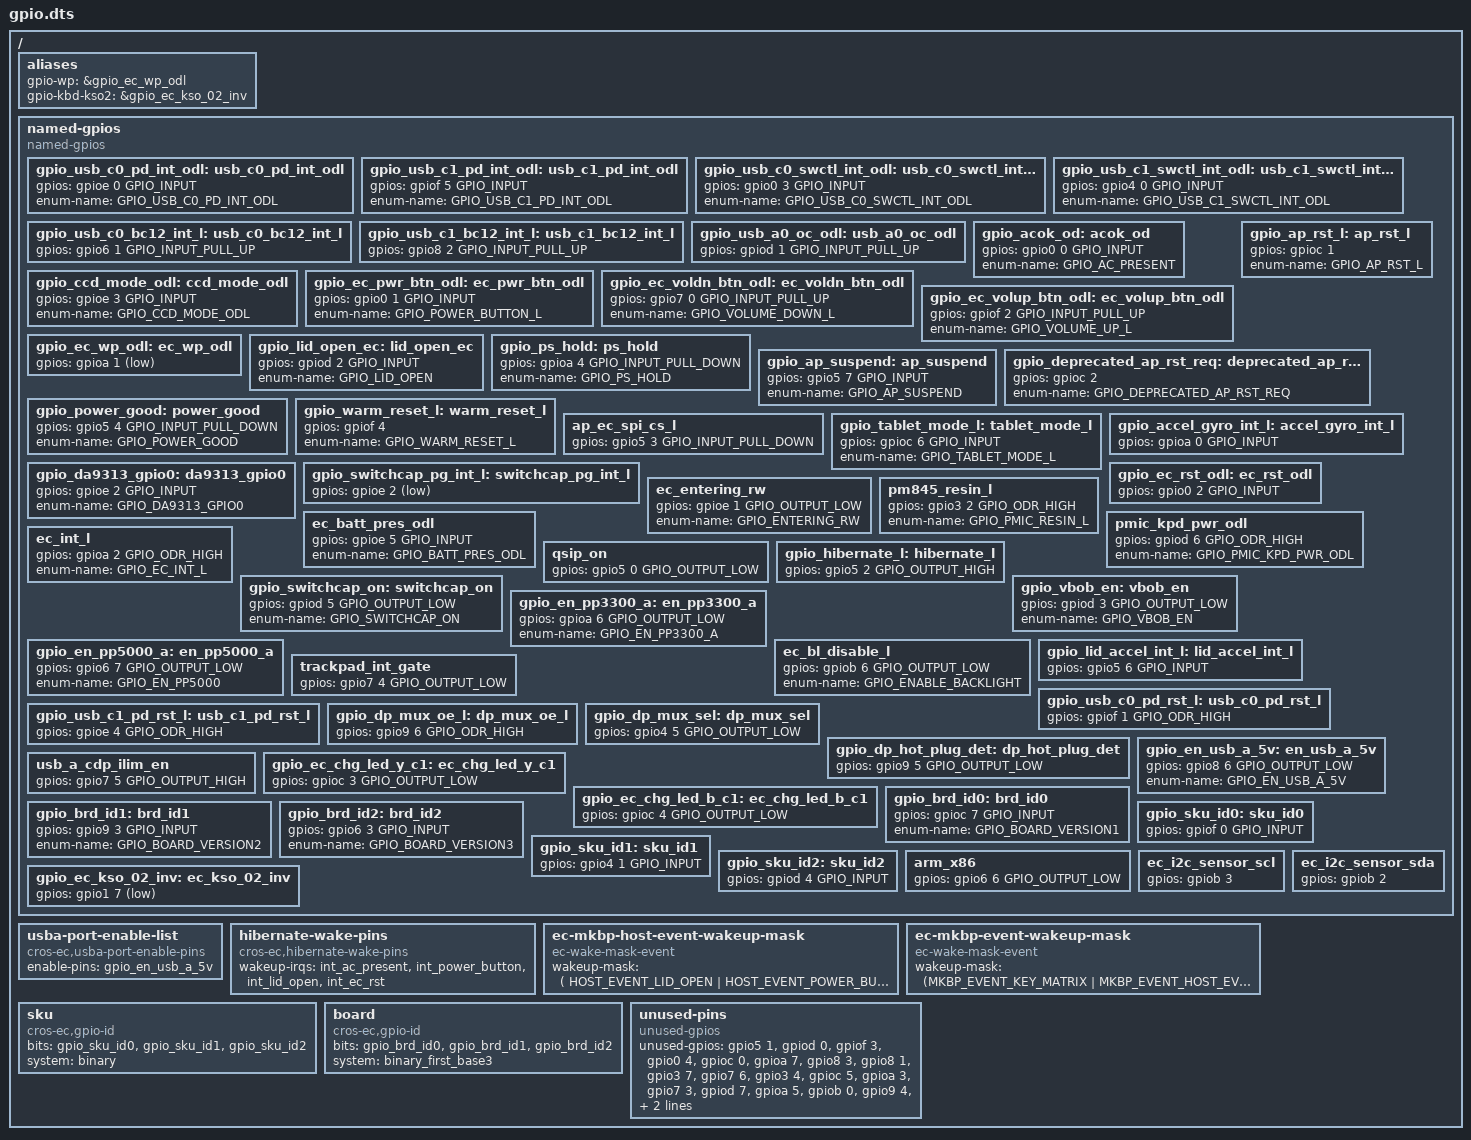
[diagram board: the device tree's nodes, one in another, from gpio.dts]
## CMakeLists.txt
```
# Copyright 2021 The ChromiumOS Authors. All rights reserved.
# Use of this source code is governed by a BSD-style license that can be
# found in the LICENSE file.

cmake_minimum_required(VERSION 3.13.1)

find_package(Zephyr REQUIRED HINTS $ENV{ZEPHYR_BASE})
project(lazor)

cros_ec_library_include_directories(include)

zephyr_library_sources_ifdef(CONFIG_PLATFORM_EC_USBC
  "src/power.c"
  "src/usb_pd_policy.c"
  "src/usbc_config.c")

zephyr_library_sources(
  "src/sku.c"
  "src/switchcap.c")

# Board specific implementation
zephyr_library_sources_ifdef(CONFIG_PLATFORM_EC_I2C
  "src/i2c.c")
```

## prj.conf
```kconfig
# Copyright 2021 The ChromiumOS Authors
# Use of this source code is governed by a BSD-style license that can be
# found in the LICENSE file.

CONFIG_CROS_EC=y
#
# Lazor actually has a NPCX7M6FC, but
# the NPCX7M7FC is actually the same die, without the
# extra RAM being tested. The code size really could
# do with the extra space, so we pretend the EC is the
# part with the larger RAM. YMMV.
#
CONFIG_SOC_NPCX7M7FC=y
CONFIG_SOC_SERIES_NPCX7=y
CONFIG_SHIMMED_TASKS=y
CONFIG_PLATFORM_EC=y
CONFIG_PLATFORM_EC_BRINGUP=y
CONFIG_PLATFORM_EC_EXTPOWER_GPIO=y
CONFIG_PLATFORM_EC_SWITCH=y
CONFIG_PLATFORM_EC_LID_SWITCH=y
CONFIG_PLATFORM_EC_BACKLIGHT_LID=y
CONFIG_PLATFORM_EC_POWER_BUTTON=y

# PWM
CONFIG_PWM=y
CONFIG_PWM_SHELL=n

# Application Processor is Qualcomm SC7180
CONFIG_AP_ARM_QUALCOMM_SC7180=y

# Board version is selected over GPIO board ID pins.
CONFIG_PLATFORM_EC_BOARD_VERSION_GPIO=y

# LN9310 Switchcap
CONFIG_PLATFORM_EC_SWITCHCAP_LN9310=y

# Power Sequencing
CONFIG_PLATFORM_EC_POWERSEQ=y
CONFIG_PLATFORM_EC_POWERSEQ_HOST_SLEEP=y
CONFIG_PLATFORM_EC_POWER_SLEEP_FAILURE_DETECTION=y
CONFIG_PLATFORM_EC_CHIPSET_RESET_HOOK=y
CONFIG_PLATFORM_EC_CHIPSET_RESUME_INIT_HOOK=y

# Trogdor family does not use EFS2
CONFIG_PLATFORM_EC_VBOOT_EFS2=n

# MKBP event
CONFIG_PLATFORM_EC_MKBP_EVENT=y
CONFIG_PLATFORM_EC_MKBP_USE_GPIO=y

# Keyboard
CONFIG_PLATFORM_EC_KEYBOARD=y
CONFIG_PLATFORM_EC_KEYBOARD_PROTOCOL_MKBP=y
CONFIG_PLATFORM_EC_MKBP_INPUT_DEVICES=y
CONFIG_PLATFORM_EC_KEYBOARD_COL2_INVERTED=y
CONFIG_PLATFORM_EC_VOLUME_BUTTONS=y
CONFIG_PLATFORM_EC_CMD_BUTTON=y
CONFIG_CROS_KB_RAW_NPCX=y

# ADC
CONFIG_ADC=y
CONFIG_ADC_SHELL=n

# Battery
CONFIG_PLATFORM_EC_BATTERY=y
CONFIG_PLATFORM_EC_BATTERY_SMART=y
CONFIG_PLATFORM_EC_I2C_VIRTUAL_BATTERY=y
CONFIG_PLATFORM_EC_I2C_PASSTHRU_RESTRICTED=y
CONFIG_PLATFORM_EC_BATTERY_FUEL_GAUGE=y
CONFIG_PLATFORM_EC_BATTERY_CUT_OFF=y
CONFIG_PLATFORM_EC_BATTERY_PRESENT_GPIO=y
CONFIG_PLATFORM_EC_CHARGER_ISL9238=y
CONFIG_PLATFORM_EC_CHARGE_RAMP_HW=y
CONFIG_PLATFORM_EC_USE_BATTERY_DEVICE_CHEMISTRY=y
CONFIG_PLATFORM_EC_BATTERY_DEVICE_CHEMISTRY="LION"
CONFIG_PLATFORM_EC_BATTERY_REVIVE_DISCONNECT=y
CONFIG_PLATFORM_EC_CHARGER_DISCHARGE_ON_AC=y
CONFIG_PLATFORM_EC_CHARGER_DISCHARGE_ON_AC_CHARGER=y
CONFIG_PLATFORM_EC_CHARGER_MIN_BAT_PCT_FOR_POWER_ON=2
CONFIG_PLATFORM_EC_CHARGER_MIN_POWER_MW_FOR_POWER_ON=10000
CONFIG_PLATFORM_EC_CHARGER_PROFILE_OVERRIDE=y
CONFIG_PLATFORM_EC_CHARGER_PSYS=y
CONFIG_PLATFORM_EC_CHARGER_PSYS_READ=y
CONFIG_PLATFORM_EC_CHARGER_SENSE_RESISTOR=10
CONFIG_PLATFORM_EC_CHARGER_SENSE_RESISTOR_AC=20
CONFIG_PLATFORM_EC_CONSOLE_CMD_CHARGER_ADC_AMON_BMON=y

# USB-A
CONFIG_PLATFORM_EC_USBA=y

# USB-C
CONFIG_PLATFORM_EC_BC12_DETECT_PI3USB9201=y
CONFIG_PLATFORM_EC_USB_PD_USB32_DRD=n
CONFIG_PLATFORM_EC_USBC_RETIMER_FW_UPDATE=n
CONFIG_PLATFORM_EC_USBC_SS_MUX_DFP_ONLY=y
CONFIG_PLATFORM_EC_USB_DRP_ACC_TRYSRC=y
CONFIG_PLATFORM_EC_USB_PD_5V_EN_CUSTOM=y
CONFIG_PLATFORM_EC_USB_PD_VBUS_DETECT_TCPC=y
CONFIG_PLATFORM_EC_USB_PD_DISCHARGE_PPC=y
CONFIG_PLATFORM_EC_USB_PD_REV30=n
CONFIG_PLATFORM_EC_USB_PD_TBT_COMPAT_MODE=n
CONFIG_PLATFORM_EC_USB_PD_USB4=n
CONFIG_PLATFORM_EC_USB_PD_TCPC_LOW_POWER=y
CONFIG_PLATFORM_EC_USB_PD_TCPM_MULTI_PS8XXX=y
CONFIG_PLATFORM_EC_USB_PD_TCPM_PS8751=y
CONFIG_PLATFORM_EC_USB_PD_TCPM_PS8805=y
CONFIG_PLATFORM_EC_USB_PD_TCPC_RUNTIME_CONFIG=n
CONFIG_PLATFORM_EC_USB_MUX_RUNTIME_CONFIG=n
CONFIG_PLATFORM_EC_USB_PD_LOGGING=y

# USB ID
# This is allocated specifically for Trogdor
# http://google3/hardware/standards/usb/
# TODO(b/183608112): Move to device tree
CONFIG_PLATFORM_EC_USB_PID=0x5043

# RTC
CONFIG_PLATFORM_EC_RTC=y
CONFIG_CROS_RTC_NPCX=y
CONFIG_PLATFORM_EC_HOSTCMD_RTC=y
CONFIG_PLATFORM_EC_CONSOLE_CMD_RTC=y

# EC software sync
CONFIG_PLATFORM_EC_VBOOT_HASH=y

# Sensors
CONFIG_PLATFORM_EC_MOTIONSENSE=y
CONFIG_PLATFORM_EC_ACCEL_FIFO=y
CONFIG_PLATFORM_EC_CONSOLE_CMD_ACCELS=y
CONFIG_PLATFORM_EC_CONSOLE_CMD_ACCEL_INFO=y
CONFIG_PLATFORM_EC_GMR_TABLET_MODE=y
CONFIG_PLATFORM_EC_LID_ANGLE=y
CONFIG_PLATFORM_EC_LID_ANGLE_UPDATE=y
CONFIG_PLATFORM_EC_SENSOR_TIGHT_TIMESTAMPS=y
CONFIG_PLATFORM_EC_TABLET_MODE=y
CONFIG_PLATFORM_EC_TABLET_MODE_SWITCH=y

# Sensor Drivers
CONFIG_PLATFORM_EC_ACCEL_BMA255=y
CONFIG_PLATFORM_EC_ACCELGYRO_BMI160=y
CONFIG_PLATFORM_EC_ACCELGYRO_BMI_COMM_I2C=y

# Console history
CONFIG_SHELL_HISTORY=y
CONFIG_SHELL_CMDS=y
CONFIG_SHELL_HELP=n
CONFIG_SHELL_MINIMAL=y

# Taskinfo
CONFIG_THREAD_MONITOR=y
CONFIG_KERNEL_SHELL=y

CONFIG_SYSCON=y

# Features should be enabled. But the code RAM is not enough, disable them.
#CONFIG_PLATFORM_EC_ACCEL_SPOOF_MODE=y
#CONFIG_PLATFORM_EC_EMULATED_SYSRQ=y
```

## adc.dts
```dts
/* Copyright 2022 The ChromiumOS Authors. All rights reserved.
 * Use of this source code is governed by a BSD-style license that can be
 * found in the LICENSE file.
 */

#include <zephyr/dt-bindings/adc/adc.h>

/ {
	named-adc-channels {
		compatible = "named-adc-channels";

		vbus {
			enum-name = "ADC_VBUS";
			io-channels = <&adc0 1>;
			/* Measure VBUS through a 1/10 voltage divider */
			mul = <10>;
		};
		amon_bmon {
			enum-name = "ADC_AMON_BMON";
			io-channels = <&adc0 2>;
			/*
			 * Adapter current output or battery charging/
			 * discharging current (uV) 18x amplification on
			 * charger side.
			 */
			mul = <1000>;
			div = <18>;
		};
		psys {
			enum-name = "ADC_PSYS";
			io-channels = <&adc0 3>;
			/*
			 * ISL9238 PSYS output is 1.44 uA/W over 5.6K resistor,
			 * to read 0.8V @ 99 W, i.e. 124000 uW/mV.
			 */
			mul = <124000>;
		};
	};

};

&adc0 {
	status = "okay";
	pinctrl-0 = <&adc0_chan1_gp44
		     &adc0_chan2_gp43
		     &adc0_chan3_gp42>;
	pinctrl-names = "default";
};
```

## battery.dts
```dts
/* Copyright 2021 The ChromiumOS Authors. All rights reserved.
 * Use of this source code is governed by a BSD-style license that can be
 * found in the LICENSE file.
 */

/ {
	batteries {
		default_battery: ap16l5j {
			compatible = "panasonic,ap16l5j", "battery-smart";
		};
		ap16l5j_009 {
			compatible = "panasonic,ap16l5j-009", "battery-smart";
		};
		ap16l8j {
			compatible = "lgc,ap16l8j", "battery-smart";
		};
		lgc_ap18c8k {
			compatible = "lgc,ap18c8k", "battery-smart";
		};
		murata_ap18c4k {
			compatible = "murata,ap18c4k", "battery-smart";
		};
	};
};
```

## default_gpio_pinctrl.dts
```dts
/* Copyright 2022 The ChromiumOS Authors. All rights reserved.
 * Use of this source code is governed by a BSD-style license that can be
 * found in the LICENSE file.
 */

/* Adds the &alt1_no_lpc_espi setting over the NPCX7 default setting. */
&{/def-io-conf-list} {
	pinmux = <&alt0_gpio_no_spip
		  &alt0_gpio_no_fpip
		  &alt1_no_pwrgd
		  &alt1_no_lpc_espi
		  &alta_no_peci_en
		  &altd_npsl_in1_sl
		  &altd_npsl_in2_sl
		  &altd_psl_in3_sl
		  &altd_psl_in4_sl
		  &alt7_no_ksi0_sl
		  &alt7_no_ksi1_sl
		  &alt7_no_ksi2_sl
		  &alt7_no_ksi3_sl
		  &alt7_no_ksi4_sl
		  &alt7_no_ksi5_sl
		  &alt7_no_ksi6_sl
		  &alt7_no_ksi7_sl
		  &alt8_no_kso00_sl
		  &alt8_no_kso01_sl
		  &alt8_no_kso02_sl
		  &alt8_no_kso03_sl
		  &alt8_no_kso04_sl
		  &alt8_no_kso05_sl
		  &alt8_no_kso06_sl
		  &alt8_no_kso07_sl
		  &alt9_no_kso08_sl
		  &alt9_no_kso09_sl
		  &alt9_no_kso10_sl
		  &alt9_no_kso11_sl
		  &alt9_no_kso12_sl
		  &alt9_no_kso13_sl
		  &alt9_no_kso14_sl
		  &alt9_no_kso15_sl
		  &alta_no_kso16_sl
		  &alta_no_kso17_sl >;
};
```

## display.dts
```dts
/* Copyright 2022 The ChromiumOS Authors. All rights reserved.
 * Use of this source code is governed by a BSD-style license that can be
 * found in the LICENSE file.
 */

/ {
	displight {
		compatible = "cros-ec,displight";
		pwms = <&pwm5 0 PWM_HZ(4800) PWM_POLARITY_NORMAL>;
		generic-pwm-channel = <1>;
	};
};

&pwm5 {
	status = "okay";
	pinctrl-0 = <&pwm5_gpb7>;
	pinctrl-names = "default";
};
```

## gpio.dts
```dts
/* Copyright 2021 The Chromium OS Authors. All rights reserved.
 * Use of this source code is governed by a BSD-style license that can be
 * found in the LICENSE file.
 */

#include <dt-bindings/wake_mask_event_defines.h>

/ {
	aliases {
		gpio-wp = &gpio_ec_wp_odl;
		gpio-kbd-kso2 = &gpio_ec_kso_02_inv;
	};

	named-gpios {
		compatible = "named-gpios";

		gpio_usb_c0_pd_int_odl: usb_c0_pd_int_odl {
			gpios = <&gpioe 0 GPIO_INPUT>;
			enum-name = "GPIO_USB_C0_PD_INT_ODL";
		};
		gpio_usb_c1_pd_int_odl: usb_c1_pd_int_odl {
			gpios = <&gpiof 5 GPIO_INPUT>;
			enum-name = "GPIO_USB_C1_PD_INT_ODL";
		};
		gpio_usb_c0_swctl_int_odl: usb_c0_swctl_int_odl {
			gpios = <&gpio0 3 GPIO_INPUT>;
			enum-name = "GPIO_USB_C0_SWCTL_INT_ODL";
		};
		gpio_usb_c1_swctl_int_odl: usb_c1_swctl_int_odl {
			gpios = <&gpio4 0 GPIO_INPUT>;
			enum-name = "GPIO_USB_C1_SWCTL_INT_ODL";
		};
		gpio_usb_c0_bc12_int_l: usb_c0_bc12_int_l {
			gpios = <&gpio6 1 GPIO_INPUT_PULL_UP>;
		};
		gpio_usb_c1_bc12_int_l: usb_c1_bc12_int_l {
			gpios = <&gpio8 2 GPIO_INPUT_PULL_UP>;
		};
		gpio_usb_a0_oc_odl: usb_a0_oc_odl {
			gpios = <&gpiod 1 GPIO_INPUT_PULL_UP>;
		};
		gpio_acok_od: acok_od {
			gpios = <&gpio0 0 GPIO_INPUT>;
			enum-name = "GPIO_AC_PRESENT";
		};
		gpio_ccd_mode_odl: ccd_mode_odl {
			gpios = <&gpioe 3 GPIO_INPUT>;
			enum-name = "GPIO_CCD_MODE_ODL";
		};
		gpio_ec_pwr_btn_odl: ec_pwr_btn_odl {
			gpios = <&gpio0 1 GPIO_INPUT>;
			enum-name = "GPIO_POWER_BUTTON_L";
		};
		gpio_ec_voldn_btn_odl: ec_voldn_btn_odl {
			gpios = <&gpio7 0 GPIO_INPUT_PULL_UP>;
			enum-name = "GPIO_VOLUME_DOWN_L";
		};
		gpio_ec_volup_btn_odl: ec_volup_btn_odl {
			gpios = <&gpiof 2 GPIO_INPUT_PULL_UP>;
			enum-name = "GPIO_VOLUME_UP_L";
		};
		gpio_ec_wp_odl: ec_wp_odl {
			gpios = <&gpioa 1 (GPIO_INPUT | GPIO_ACTIVE_LOW)>;
		};
		gpio_lid_open_ec: lid_open_ec {
			gpios = <&gpiod 2 GPIO_INPUT>;
			enum-name = "GPIO_LID_OPEN";
		};
		gpio_ap_rst_l: ap_rst_l {
			gpios = <&gpioc 1 (GPIO_INPUT | GPIO_VOLTAGE_1P8)>;
			enum-name = "GPIO_AP_RST_L";
		};
		gpio_ps_hold: ps_hold {
			gpios = <&gpioa 4 GPIO_INPUT_PULL_DOWN>;
			enum-name = "GPIO_PS_HOLD";
		};
		gpio_ap_suspend: ap_suspend {
			gpios = <&gpio5 7 GPIO_INPUT>;
			enum-name = "GPIO_AP_SUSPEND";
		};
		gpio_deprecated_ap_rst_req: deprecated_ap_rst_req {
			gpios = <&gpioc 2 (GPIO_INPUT_PULL_DOWN | GPIO_VOLTAGE_1P8)>;
			enum-name = "GPIO_DEPRECATED_AP_RST_REQ";
		};
		gpio_power_good: power_good {
			gpios = <&gpio5 4 GPIO_INPUT_PULL_DOWN>;
			enum-name = "GPIO_POWER_GOOD";
		};
		gpio_warm_reset_l: warm_reset_l {
			gpios = <&gpiof 4 (GPIO_INPUT | GPIO_VOLTAGE_1P8)>;
			enum-name = "GPIO_WARM_RESET_L";
		};
		ap_ec_spi_cs_l {
			gpios = <&gpio5 3 GPIO_INPUT_PULL_DOWN>;
		};
		gpio_tablet_mode_l: tablet_mode_l {
			gpios = <&gpioc 6 GPIO_INPUT>;
			enum-name = "GPIO_TABLET_MODE_L";
		};
		gpio_accel_gyro_int_l: accel_gyro_int_l {
			gpios = <&gpioa 0 GPIO_INPUT>;
		};
		gpio_da9313_gpio0: da9313_gpio0 {
			gpios = <&gpioe 2 GPIO_INPUT>;
			enum-name = "GPIO_DA9313_GPIO0";
		};
		/*
		 * Active low input
		 */
		gpio_switchcap_pg_int_l: switchcap_pg_int_l {
			gpios = <&gpioe 2 (GPIO_ACTIVE_LOW | GPIO_INPUT)>;
		};
		gpio_ec_rst_odl: ec_rst_odl {
			gpios = <&gpio0 2 GPIO_INPUT>;
		};
		ec_entering_rw {
			gpios = <&gpioe 1 GPIO_OUTPUT_LOW>;
			enum-name = "GPIO_ENTERING_RW";
		};
		ec_batt_pres_odl {
			gpios = <&gpioe 5 GPIO_INPUT>;
			enum-name = "GPIO_BATT_PRES_ODL";
		};
		pm845_resin_l {
			gpios = <&gpio3 2 GPIO_ODR_HIGH>;
			enum-name = "GPIO_PMIC_RESIN_L";
		};
		pmic_kpd_pwr_odl {
			gpios = <&gpiod 6 GPIO_ODR_HIGH>;
			enum-name = "GPIO_PMIC_KPD_PWR_ODL";
		};
		ec_int_l {
			gpios = <&gpioa 2 GPIO_ODR_HIGH>;
			enum-name = "GPIO_EC_INT_L";
		};
		qsip_on {
			gpios = <&gpio5 0 GPIO_OUTPUT_LOW>;
		};
		gpio_hibernate_l: hibernate_l {
			gpios = <&gpio5 2 GPIO_OUTPUT_HIGH>;
		};
		gpio_switchcap_on: switchcap_on {
			gpios = <&gpiod 5 GPIO_OUTPUT_LOW>;
			enum-name = "GPIO_SWITCHCAP_ON";
		};
		gpio_vbob_en: vbob_en {
			gpios = <&gpiod 3 GPIO_OUTPUT_LOW>;
			enum-name = "GPIO_VBOB_EN";
		};
		gpio_en_pp3300_a: en_pp3300_a {
			gpios = <&gpioa 6 GPIO_OUTPUT_LOW>;
			enum-name = "GPIO_EN_PP3300_A";
		};
		gpio_en_pp5000_a: en_pp5000_a {
			gpios = <&gpio6 7 GPIO_OUTPUT_LOW>;
			enum-name = "GPIO_EN_PP5000";
		};
		ec_bl_disable_l {
			gpios = <&gpiob 6 GPIO_OUTPUT_LOW>;
			enum-name = "GPIO_ENABLE_BACKLIGHT";
		};
		gpio_lid_accel_int_l: lid_accel_int_l {
			gpios = <&gpio5 6 GPIO_INPUT>;
		};
		trackpad_int_gate {
			gpios = <&gpio7 4 GPIO_OUTPUT_LOW>;
		};
		gpio_usb_c0_pd_rst_l: usb_c0_pd_rst_l {
			gpios = <&gpiof 1 GPIO_ODR_HIGH>;
		};
		gpio_usb_c1_pd_rst_l: usb_c1_pd_rst_l {
			gpios = <&gpioe 4 GPIO_ODR_HIGH>;
		};
		gpio_dp_mux_oe_l: dp_mux_oe_l {
			gpios = <&gpio9 6 GPIO_ODR_HIGH>;
		};
		gpio_dp_mux_sel: dp_mux_sel {
			gpios = <&gpio4 5 GPIO_OUTPUT_LOW>;
		};
		gpio_dp_hot_plug_det: dp_hot_plug_det {
			gpios = <&gpio9 5 GPIO_OUTPUT_LOW>;
		};
		gpio_en_usb_a_5v: en_usb_a_5v {
			gpios = <&gpio8 6 GPIO_OUTPUT_LOW>;
			enum-name = "GPIO_EN_USB_A_5V";
		};
		usb_a_cdp_ilim_en {
			gpios = <&gpio7 5 GPIO_OUTPUT_HIGH>;
		};
		gpio_ec_chg_led_y_c1: ec_chg_led_y_c1 {
			#led-pin-cells = <1>;
			gpios = <&gpioc 3 GPIO_OUTPUT_LOW>;
		};
		gpio_ec_chg_led_b_c1: ec_chg_led_b_c1 {
			#led-pin-cells = <1>;
			gpios = <&gpioc 4 GPIO_OUTPUT_LOW>;
		};
		gpio_brd_id0: brd_id0 {
			gpios = <&gpioc 7 GPIO_INPUT>;
			enum-name = "GPIO_BOARD_VERSION1";
		};
		gpio_brd_id1: brd_id1 {
			gpios = <&gpio9 3 GPIO_INPUT>;
			enum-name = "GPIO_BOARD_VERSION2";
		};
		gpio_brd_id2: brd_id2 {
			gpios = <&gpio6 3 GPIO_INPUT>;
			enum-name = "GPIO_BOARD_VERSION3";
		};
		gpio_sku_id0: sku_id0 {
			gpios = <&gpiof 0 GPIO_INPUT>;
		};
		gpio_sku_id1: sku_id1 {
			gpios = <&gpio4 1 GPIO_INPUT>;
		};
		gpio_sku_id2: sku_id2 {
			gpios = <&gpiod 4 GPIO_INPUT>;
		};
		arm_x86 {
			gpios = <&gpio6 6 GPIO_OUTPUT_LOW>;
		};
		ec_i2c_sensor_scl {
			gpios = <&gpiob 3 (GPIO_INPUT | GPIO_VOLTAGE_1P8)>;
		};
		ec_i2c_sensor_sda {
			gpios = <&gpiob 2 (GPIO_INPUT | GPIO_VOLTAGE_1P8)>;
		};
		gpio_ec_kso_02_inv: ec_kso_02_inv {
			gpios = <&gpio1 7 (GPIO_OUTPUT_LOW | GPIO_ACTIVE_LOW)>;
		};
	};

	usba-port-enable-list {
		compatible = "cros-ec,usba-port-enable-pins";
		enable-pins = <&gpio_en_usb_a_5v>;
	};

	hibernate-wake-pins {
		compatible = "cros-ec,hibernate-wake-pins";
		wakeup-irqs = <
			&int_ac_present
			&int_power_button
			&int_lid_open
			&int_ec_rst
		>;
	};

	ec-mkbp-host-event-wakeup-mask {
		compatible = "ec-wake-mask-event";
		wakeup-mask = <(
			HOST_EVENT_LID_OPEN |
			HOST_EVENT_POWER_BUTTON |
			HOST_EVENT_AC_CONNECTED |
			HOST_EVENT_AC_DISCONNECTED |
			HOST_EVENT_HANG_DETECT |
			HOST_EVENT_RTC |
			HOST_EVENT_MODE_CHANGE |
			HOST_EVENT_DEVICE)>;
	};

	ec-mkbp-event-wakeup-mask {
		compatible = "ec-wake-mask-event";
		wakeup-mask = <(MKBP_EVENT_KEY_MATRIX |
				MKBP_EVENT_HOST_EVENT |
				MKBP_EVENT_SENSOR_FIFO)>;
	};

	sku {
		compatible = "cros-ec,gpio-id";

		bits  = <
			&gpio_sku_id0
			&gpio_sku_id1
			&gpio_sku_id2
		>;

		system = "binary";
	};

	board {
		compatible = "cros-ec,gpio-id";

		bits  = <
			&gpio_brd_id0
			&gpio_brd_id1
			&gpio_brd_id2
		>;

		system = "binary_first_base3";
	};

	unused-pins {
		compatible = "unused-gpios";
		unused-gpios =
			<&gpio5 1 0>,
			<&gpiod 0 0>,
			<&gpiof 3 0>,
			<&gpio0 4 0>,
			<&gpioc 0 0>,
			<&gpioa 7 0>,
			<&gpio8 3 0>,
			<&gpio8 1 0>,
			<&gpio3 7 0>,
			<&gpio7 6 0>,
			<&gpio3 4 0>,
			<&gpioc 5 0>,
			<&gpioa 3 0>,
			<&gpio7 3 0>,
			<&gpiod 7 0>,
			<&gpioa 5 0>,
			<&gpiob 0 0>,
			<&gpio9 4 0>,
			<&gpiob 1 0>,
			<&gpio6 2 0>,
			<&gpio3 5 0>,
			<&gpio9 7 0>,
			<&gpio6 0 0>,
			<&gpio7 2 0>;
	};
};
```

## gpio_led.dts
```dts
/* Copyright 2022 The ChromiumOS Authors. All rights reserved.
 * Use of this source code is governed by a BSD-style license that can be
 * found in the LICENSE file.
 */

/ {
	gpio-led-pins {
		compatible = "cros-ec,gpio-led-pins";

		color_off: color-off {
			led-color = "LED_OFF";
			led-id = "EC_LED_ID_BATTERY_LED";
			led-pins = <&gpio_ec_chg_led_y_c1 0>,
				   <&gpio_ec_chg_led_b_c1 0>;
		};

		color_amber: color-amber {
			led-color = "LED_AMBER";
			led-id = "EC_LED_ID_BATTERY_LED";
			br-color = "EC_LED_COLOR_AMBER";
			led-pins = <&gpio_ec_chg_led_y_c1 1>,
				   <&gpio_ec_chg_led_b_c1 0>;
		};

		color_blue: color-blue {
			led-color = "LED_BLUE";
			led-id = "EC_LED_ID_BATTERY_LED";
			br-color = "EC_LED_COLOR_BLUE";
			led-pins = <&gpio_ec_chg_led_y_c1 0>,
				   <&gpio_ec_chg_led_b_c1 1>;
		};
	};
};
```

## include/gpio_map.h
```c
/* Copyright 2021 The Chromium OS Authors. All rights reserved.
 * Use of this source code is governed by a BSD-style license that can be
 * found in the LICENSE file.
 */

#ifndef __ZEPHYR_GPIO_MAP_H
#define __ZEPHYR_GPIO_MAP_H

#include <devicetree.h>
#include <gpio_signal.h>

#ifdef CONFIG_PLATFORM_EC_GMR_TABLET_MODE
#define GMR_TABLET_MODE_GPIO_L GPIO_TABLET_MODE_L
#endif

/*
 * Set EC_CROS_GPIO_INTERRUPTS to a space-separated list of GPIO_INT items.
 *
 * Each GPIO_INT requires three parameters:
 *   gpio_signal - The enum gpio_signal for the interrupt gpio
 *   interrupt_flags - The interrupt-related flags (e.g. GPIO_INT_EDGE_BOTH)
 *   handler - The platform/ec interrupt handler.
 *
 * Ensure that this files includes all necessary headers to declare all
 * referenced handler functions.
 *
 * For example, one could use the follow definition:
 * #define EC_CROS_GPIO_INTERRUPTS \
 *   GPIO_INT(NAMED_GPIO(h1_ec_pwr_btn_odl), GPIO_INT_EDGE_BOTH, button_print)
 */
#define EC_CROS_GPIO_INTERRUPTS                                               \
	GPIO_INT(GPIO_AC_PRESENT, GPIO_INT_EDGE_BOTH, extpower_interrupt)     \
	GPIO_INT(GPIO_LID_OPEN, GPIO_INT_EDGE_BOTH, lid_interrupt)            \
	GPIO_INT(GPIO_WP_L, GPIO_INT_EDGE_BOTH, switch_interrupt)             \
	GPIO_INT(GPIO_POWER_BUTTON_L, GPIO_INT_EDGE_BOTH,                     \
		 power_button_interrupt)                                      \
	GPIO_INT(GPIO_VOLUME_DOWN_L, GPIO_INT_EDGE_BOTH, button_interrupt)    \
	GPIO_INT(GPIO_VOLUME_UP_L, GPIO_INT_EDGE_BOTH, button_interrupt)      \
	GPIO_INT(GPIO_SWITCHCAP_PG_INT_L, GPIO_INT_EDGE_FALLING,              \
		 ln9310_interrupt)                                            \
	GPIO_INT(GPIO_AP_RST_L, GPIO_INT_EDGE_BOTH, chipset_ap_rst_interrupt) \
	GPIO_INT(GPIO_AP_SUSPEND, GPIO_INT_EDGE_BOTH, power_signal_interrupt) \
	GPIO_INT(GPIO_DEPRECATED_AP_RST_REQ, GPIO_INT_EDGE_BOTH,              \
		 power_signal_interrupt)                                      \
	GPIO_INT(GPIO_POWER_GOOD, GPIO_INT_EDGE_BOTH,                         \
		 chipset_power_good_interrupt)                                \
	GPIO_INT(GPIO_PS_HOLD, GPIO_INT_EDGE_BOTH, power_signal_interrupt)    \
	GPIO_INT(GPIO_WARM_RESET_L, GPIO_INT_EDGE_BOTH,                       \
		 chipset_warm_reset_interrupt)                                \
	GPIO_INT(GPIO_USB_C0_PD_INT_ODL, GPIO_INT_EDGE_FALLING,               \
		 tcpc_alert_event)                                            \
	GPIO_INT(GPIO_USB_C1_PD_INT_ODL, GPIO_INT_EDGE_FALLING,               \
		 tcpc_alert_event)                                            \
	GPIO_INT(GPIO_USB_C0_SWCTL_INT_ODL, GPIO_INT_EDGE_FALLING,            \
		 ppc_interrupt)                                               \
	GPIO_INT(GPIO_USB_C1_SWCTL_INT_ODL, GPIO_INT_EDGE_FALLING,            \
		 ppc_interrupt)                                               \
	GPIO_INT(GPIO_USB_C0_BC12_INT_L, GPIO_INT_EDGE_FALLING, usb0_evt)     \
	GPIO_INT(GPIO_USB_C1_BC12_INT_L, GPIO_INT_EDGE_FALLING, usb1_evt)     \
	GPIO_INT(GPIO_USB_A0_OC_ODL, GPIO_INT_EDGE_BOTH, usba_oc_interrupt)   \
	GPIO_INT(GPIO_CCD_MODE_ODL, GPIO_INT_EDGE_FALLING,                    \
		 board_connect_c0_sbu)                                        \
	GPIO_INT(GPIO_ACCEL_GYRO_INT_L, GPIO_INT_EDGE_FALLING,                \
		 bmi160_interrupt)                                            \
	GPIO_INT(GPIO_TABLET_MODE_L, GPIO_INT_EDGE_BOTH, gmr_tablet_switch_isr)

#define EC_CROS_IOEX_INTERRUPTS \
	IOEX_INT(IOEX_FAKE5, GPIO_INT_EDGE_BOTH, ioex_test_interrupt)

#endif /* __ZEPHYR_GPIO_MAP_H */
```

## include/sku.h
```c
/* Copyright 2022 The ChromiumOS Authors. All rights reserved.
 * Use of this source code is governed by a BSD-style license that can be
 * found in the LICENSE file.
 */

/* Lazor board-specific SKU configuration */

#ifndef __ZEPHYR_LAZOR_SKU_H
#define __ZEPHYR_LAZOR_SKU_H

int board_get_version(void);
int board_is_clamshell(void);
int board_has_da9313(void);
int board_has_ln9310(void);
int board_has_buck_ic(void);

#endif /* __ZEPHYR_LAZOR_SKU_H */
```

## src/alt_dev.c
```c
/* Copyright 2021 The Chromium OS Authors. All rights reserved.
 * Use of this source code is governed by a BSD-style license that can be
 * found in the LICENSE file.
 */

#include "i2c/i2c.h"
#include "i2c.h"
#include "hooks.h"
#include "motionsense_sensors.h"
#include "system.h"

static void check_alternate_devices(void)
{
	MOTIONSENSE_PROBE_AND_ENABLE_ALTERNATE(alt_lid_accel);

	if (system_get_sku_id() != 99) {
		MOTIONSENSE_ENABLE_ALTERNATE(alt_lid_accel);
	}
}
DECLARE_HOOK(HOOK_INIT, check_alternate_devices, HOOK_PRIO_INIT_I2C + 2);
```

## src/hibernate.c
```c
/* Copyright 2022 The ChromiumOS Authors. All rights reserved.
 * Use of this source code is governed by a BSD-style license that can be
 * found in the LICENSE file.
 */

#include "common.h"
#include "sku.h"
#include "system.h"
#include "usbc_ppc.h"

void board_hibernate(void)
{
	int i;

	if (!board_is_clamshell()) {
		/*
		 * Sensors are unpowered in hibernate. Apply PD to the
		 * interrupt lines such that they don't float.
		 */
		gpio_pin_configure_dt(
			GPIO_DT_FROM_NODELABEL(gpio_accel_gyro_int_l),
			GPIO_DISCONNECTED);
		gpio_pin_configure_dt(
			GPIO_DT_FROM_NODELABEL(gpio_lid_accel_int_l),
			GPIO_DISCONNECTED);
	}

	/*
	 * Board rev 5+ has the hardware fix. Don't need the following
	 * workaround.
	 */
	if (system_get_board_version() >= 5)
		return;

	/*
	 * Enable the PPC power sink path before EC enters hibernate;
	 * otherwise, ACOK won't go High and can't wake EC up. Check the
	 * bug b/170324206 for details.
	 */
	for (i = 0; i < CONFIG_USB_PD_PORT_MAX_COUNT; i++)
		ppc_vbus_sink_enable(i, 1);
}

void board_hibernate_late(void)
{
	/* Set the hibernate GPIO to turn off the rails */
	gpio_pin_set_dt(GPIO_DT_FROM_NODELABEL(gpio_hibernate_l), 0);
}
```

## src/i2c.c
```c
/* Copyright 2021 The ChromiumOS Authors. All rights reserved.
 * Use of this source code is governed by a BSD-style license that can be
 * found in the LICENSE file.
 */

#include "i2c/i2c.h"
#include "i2c.h"

/* Lazor board specific i2c implementation */

#ifdef CONFIG_PLATFORM_EC_I2C_PASSTHRU_RESTRICTED
int board_allow_i2c_passthru(const struct i2c_cmd_desc_t *cmd_desc)
{
	return (i2c_get_device_for_port(cmd_desc->port) ==
		i2c_get_device_for_port(I2C_PORT_VIRTUAL_BATTERY));
}
#endif
```

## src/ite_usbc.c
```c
/* Copyright 2021 The ChromiumOS Authors
 * Use of this source code is governed by a BSD-style license that can be
 * found in the LICENSE file.
 */

/* Krabby board-specific USB-C configuration */

#include "charge_manager.h"
#include "console.h"
#include "driver/tcpm/it83xx_pd.h"
#include "driver/usb_mux/tusb1064.h"
#include "i2c.h"
#include "usb_pd.h"
#include "usbc_ppc.h"
#include "variant_db_detection.h"
#include "zephyr_adc.h"

#define CPRINTSUSB(format, args...) cprints(CC_USBCHARGE, format, ##args)
#define CPRINTS(format, args...) cprints(CC_SYSTEM, format, ##args)
#define CPRINTF(format, args...) cprintf(CC_SYSTEM, format, ##args)

int tusb1064_mux_1_board_init(const struct usb_mux *me)
{
	int rv;

	rv = i2c_write8(me->i2c_port, me->i2c_addr_flags,
			TUSB1064_REG_DP1DP3EQ_SEL,
			TUSB1064_DP1EQ(TUSB1064_DP_EQ_RX_8_9_DB) |
				TUSB1064_DP3EQ(TUSB1064_DP_EQ_RX_5_4_DB));
	if (rv)
		return rv;

	/* Enable EQ_OVERRIDE so the gain registers are used */
	return i2c_update8(me->i2c_port, me->i2c_addr_flags,
			   TUSB1064_REG_GENERAL, REG_GENERAL_EQ_OVERRIDE,
			   MASK_SET);
}

#ifdef CONFIG_USB_PD_TCPM_ITE_ON_CHIP
const struct cc_para_t *board_get_cc_tuning_parameter(enum usbpd_port port)
{
	const static struct cc_para_t
		cc_parameter[CONFIG_USB_PD_ITE_ACTIVE_PORT_COUNT] = {
			{
				.rising_time =
					IT83XX_TX_PRE_DRIVING_TIME_1_UNIT,
				.falling_time =
					IT83XX_TX_PRE_DRIVING_TIME_2_UNIT,
			},
			{
				.rising_time =
					IT83XX_TX_PRE_DRIVING_TIME_1_UNIT,
				.falling_time =
					IT83XX_TX_PRE_DRIVING_TIME_2_UNIT,
			},
		};

	return &cc_parameter[port];
}
#endif

void board_reset_pd_mcu(void)
{
	/*
	 * C0 & C1: TCPC is embedded in the EC and processes interrupts in the
	 * chip code (it83xx/intc.c)
	 */
}

#ifndef CONFIG_TEST
int board_set_active_charge_port(int port)
{
	int i;
	int is_valid_port = (port >= 0 && port < board_get_usb_pd_port_count());

	if (!is_valid_port && port != CHARGE_PORT_NONE) {
		return EC_ERROR_INVAL;
	}

	if (port == CHARGE_PORT_NONE) {
		CPRINTS("Disabling all charger ports");

		/* Disable all ports. */
		for (i = 0; i < ppc_cnt; i++) {
			/*
			 * Do not return early if one fails otherwise we can
			 * get into a boot loop assertion failure.
			 */
			if (ppc_vbus_sink_enable(i, 0)) {
				CPRINTS("Disabling C%d as sink failed.", i);
			}
		}

		return EC_SUCCESS;
	}

	/* Check if the port is sourcing VBUS. */
	if (ppc_is_sourcing_vbus(port)) {
		CPRINTS("Skip enable C%d", port);
		return EC_ERROR_INVAL;
	}

	CPRINTS("New charge port: C%d", port);

	/*
	 * Turn off the other ports' sink path FETs, before enabling the
	 * requested charge port.
	 */
	for (i = 0; i < ppc_cnt; i++) {
		if (i == port) {
			continue;
		}

		if (ppc_vbus_sink_enable(i, 0)) {
			CPRINTS("C%d: sink path disable failed.", i);
		}
	}

	/* Enable requested charge port. */
	if (ppc_vbus_sink_enable(port, 1)) {
		CPRINTS("C%d: sink path enable failed.", port);
		return EC_ERROR_UNKNOWN;
	}

	return EC_SUCCESS;
}
#endif

#ifdef CONFIG_USB_PD_VBUS_MEASURE_ADC_EACH_PORT
enum adc_channel board_get_vbus_adc(int port)
{
	if (port == 0) {
		return ADC_VBUS_C0;
	}
	if (port == 1) {
		return ADC_VBUS_C1;
	}
	CPRINTSUSB("Unknown vbus adc port id: %d", port);
	return ADC_VBUS_C0;
}
#endif /* CONFIG_USB_PD_VBUS_MEASURE_ADC_EACH_PORT */
```

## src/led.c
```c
/* Copyright 2022 The Chromium OS Authors. All rights reserved.
 * Use of this source code is governed by a BSD-style license that can be
 * found in the LICENSE file.
 *
 * Power and battery LED control.
 */

#include <drivers/gpio.h>

#include "battery.h"
#include "charge_manager.h"
#include "charge_state.h"
#include "chipset.h"
#include "ec_commands.h"
#include "hooks.h"
#include "host_command.h"
#include "led_common.h"
#include "power.h"
#include "system.h"
#include "util.h"

#include <devicetree.h>
#include <logging/log.h>
LOG_MODULE_REGISTER(gpio_led, LOG_LEVEL_ERR);

#define LED_ONE_SEC (1000 / HOOK_TICK_INTERVAL_MS)

#define BAT_LED_ON 1
#define BAT_LED_OFF 0

#define GPIO_LED_NODE		DT_PATH(gpio_led, gpio_led_colors)
#define LED_COLOR_ENUMS_NODE	DT_PATH(gpio_led, led_color_enums)
#define LED_ID_ENUMS_NODE	DT_PATH(gpio_led, led_id_enums)
#define BRIGHTNESS_RANGE_NODE	DT_PATH(gpio_led, led_brightness_range)

#define LED_ENUM(id) 	 DT_STRING_TOKEN(id, enum_name)
#define LED_ENUM_WITH_COMMA(id) \
	COND_CODE_1(DT_NODE_HAS_PROP(id, enum_name), (LED_ENUM(id),), ())

const enum ec_led_id supported_led_ids[] = {
	DT_FOREACH_CHILD(LED_ID_ENUMS_NODE, LED_ENUM_WITH_COMMA)
};

const int supported_led_ids_count = ARRAY_SIZE(supported_led_ids);

enum led_color {
	LED_OFF,
	DT_FOREACH_CHILD(LED_COLOR_ENUMS_NODE, LED_ENUM_WITH_COMMA)
	LED_COLOR_COUNT,
};

static void led_set_color(enum led_color color)
{
	gpio_pin_set_dt(GPIO_DT_FROM_NODELABEL(gpio_ec_chg_led_y_c1),
		(color == LED_AMBER) ? BAT_LED_ON : BAT_LED_OFF);
	gpio_pin_set_dt(GPIO_DT_FROM_NODELABEL(gpio_ec_chg_led_b_c1),
		(color == LED_BLUE) ? BAT_LED_ON : BAT_LED_OFF);
}

void led_get_brightness_range(enum ec_led_id led_id, uint8_t *brightness_range)
{
	if (led_id == EC_LED_ID_BATTERY_LED) {
		const uint8_t dt_brigthness_range[EC_LED_COLOR_COUNT] =
		    DT_PROP(BRIGHTNESS_RANGE_NODE, brightness_range_battery);

		memcpy(brightness_range, dt_brigthness_range,
			sizeof(dt_brigthness_range));
	}
}

int led_set_brightness(enum ec_led_id led_id, const uint8_t *brightness)
{
	if (brightness[EC_LED_COLOR_BLUE] != 0)
		led_set_color(LED_BLUE);
	else if (brightness[EC_LED_COLOR_AMBER] != 0)
		led_set_color(LED_AMBER);
	else
		led_set_color(LED_OFF);

	return EC_SUCCESS;
}

struct led_color_node_t {
	int led_color;
	int acc_period;
};

enum led_extra_flag_t {
	NONE = 0,
	LED_CHFLAG_FORCE_IDLE,
	LED_CHFLAG_DEFAULT,
	LED_BATT_BELOW_10_PCT,
	LED_BATT_ABOVE_10_PCT,
};

/*
 * Currently 4 different colors are supported for blinking LED, each of which
 * can have different periods. Each period slot is the accumulation of previous
 * periods as described below. Last slot is the total accumulation which is
 * used as a dividing factor to calculate ticks to switch color
 * Eg LED_COLOR_1 1 sec, LED_COLOR_2 2 sec, LED_COLOR_3 3 sec, LED_COLOR_4 3 sec
 * period_1 = 1, period_2 = 1 + 2, period_3 = 1 + 2 + 3, period_4 =1 + 2 + 3 + 3
 * ticks -> 0, 1, 2, 3, 4, 5, 6, 7, 8, 0, 1, 2 and so on (ticks % 9)
 * 0 < period_1 -> LED_COLOR_1 for 1 sec
 * 1, 2 < period_2 -> LED_COLOR_2 for 2 secs
 * 3, 4, 5 < period_3 -> LED_COLOR_3 for 3 secs
 * 6, 7, 8 < period_4 -> LED_COLOR_4 for 3 secs
 */
#define MAX_COLOR	4

struct node_prop_t {
	enum charge_state pwr_state;
	enum power_state chipset_state;
	enum led_extra_flag_t led_extra_flag;
	struct led_color_node_t led_colors[MAX_COLOR];
};

/*
 * acc_period is the accumulated period value of all color-x children
 * led_colors[0].acc_period = period value of color-0 node
 * led_colors[1].acc_period = period value of color-0 + color-1 nodes
 * led_colors[2].acc_period = period value of color-0 + color-1 + color-2 nodes
 * and so on. If period prop or color node doesn't exist, period val is 0
 */

#define PERIOD_VAL(id) COND_CODE_1(DT_NODE_HAS_PROP(id, period),	\
				   (DT_PROP(id, period)),		\
				   (0))

#define LED_PERIOD(color_num, state_id)					\
	PERIOD_VAL(DT_CHILD(state_id, color_##color_num))

#define LED_PLUS_PERIOD(color_num, state_id)				\
	+ LED_PERIOD(color_num, state_id)

#define ACC_PERIOD(color_num, state_id)					\
	(0 LISTIFY(color_num, LED_PLUS_PERIOD, (), state_id))

#define GET_PROP(id, prop)						\
	COND_CODE_1(DT_NODE_HAS_PROP(id, prop),				\
		    (DT_STRING_UPPER_TOKEN(id, prop)),			\
		    (0))

#define LED_COLOR_INIT(color_num, color_num_plus_one, state_id)		\
{									\
	.led_color = GET_PROP(DT_CHILD(state_id, color_##color_num),	\
							led_color),	\
	.acc_period = ACC_PERIOD(color_num_plus_one, state_id)		\
}

/* Initialize node_array struct with prop listed in dts */
#define SET_LED_VALUES(state_id)					\
{									\
	.pwr_state = GET_PROP(state_id, charge_state),			\
	.chipset_state = GET_PROP(state_id, chipset_state),		\
	.led_extra_flag = GET_PROP(state_id, extra_flag),		\
	.led_colors = {LED_COLOR_INIT(0, 1, state_id),			\
		       LED_COLOR_INIT(1, 2, state_id),			\
		       LED_COLOR_INIT(2, 3, state_id),			\
		       LED_COLOR_INIT(3, 4, state_id),			\
		      }							\
},

struct node_prop_t node_array[] = {
	DT_FOREACH_CHILD(GPIO_LED_NODE, SET_LED_VALUES)
};

static enum power_state get_chipset_state(void)
{
	enum power_state chipset_state = 0;

	/*
	 * Only covers subset of power states as other states don't
	 * alter LED behavior
	 */
	if (chipset_in_state(CHIPSET_STATE_ON))
		/* S0 */
		chipset_state = POWER_S0;
	else if (chipset_in_state(CHIPSET_STATE_ANY_SUSPEND))
		/* S3 */
		chipset_state = POWER_S3;
	else if (chipset_in_state(CHIPSET_STATE_ANY_OFF))
		/* S5 */
		chipset_state = POWER_S5;

	return chipset_state;
}

static bool find_node_with_extra_flag(int i)
{
	uint32_t chflags = charge_get_flags();
	bool found_node = false;

	switch (node_array[i].led_extra_flag) {
	case LED_CHFLAG_FORCE_IDLE:
	case LED_CHFLAG_DEFAULT:
		if (chflags & CHARGE_FLAG_FORCE_IDLE) {
			if (node_array[i].led_extra_flag ==
					LED_CHFLAG_FORCE_IDLE)
				found_node = true;
		} else {
			if (node_array[i].led_extra_flag == LED_CHFLAG_DEFAULT)
				found_node = true;
		}
		break;
	case LED_BATT_BELOW_10_PCT:
	case LED_BATT_ABOVE_10_PCT:
		if (charge_get_percent() < 10) {
			if (node_array[i].led_extra_flag ==
					LED_BATT_BELOW_10_PCT)
				found_node = true;
		} else {
			if (node_array[i].led_extra_flag !=
					LED_BATT_ABOVE_10_PCT)
				found_node = true;
		}
		break;
	default:
		LOG_ERR("Invalid led extra flag %d",
				node_array[i].led_extra_flag);
		break;
	}

	return found_node;
}

static int find_node(void)
{
	int i = 0;

	for (i = 0; i < ARRAY_SIZE(node_array); i++) {
		/* Check if this node depends on power state */
		if (node_array[i].pwr_state != PWR_STATE_UNCHANGE) {
			enum charge_state pwr_state = charge_get_state();

			if (node_array[i].pwr_state != pwr_state)
				continue;
		}

		/* Check if this node depends on chipset state */
		if (node_array[i].chipset_state != 0) {
			enum power_state chipset_state =
						get_chipset_state();

			/* Continue at current index as nodes are in sequence */
			if (node_array[i].chipset_state != chipset_state)
				continue;
		}

		/* Check if the node depends on any special flags */
		if (node_array[i].led_extra_flag != NONE)
			if (!find_node_with_extra_flag(i))
				continue;

		/* We found the node */
		return i;
	}

	/*
	 * Didn't find a valid node that matches all the properties
	 * Return -1 to signify error
	 */
	return -1;
}

#define GET_PERIOD(n_idx, c_idx)  node_array[n_idx].led_colors[c_idx].acc_period
#define GET_COLOR(n_idx, c_idx)   node_array[n_idx].led_colors[c_idx].led_color

static int find_color(int node_idx, int ticks)
{
	int color_idx = 0;

	/* If period value at index 0 is not 0, it's a blinking LED */
	if (GET_PERIOD(node_idx, 0) != 0) {
		/*  Period is accumulated at the last index */
		ticks = ticks % GET_PERIOD(node_idx, MAX_COLOR - 1);

		for (color_idx = 0; color_idx < MAX_COLOR; color_idx++) {
			if (GET_PERIOD(node_idx, color_idx) > ticks)
				break;
		}
	}

	return GET_COLOR(node_idx, color_idx);
}

static void board_led_set_color(void)
{
	int color = LED_OFF;
	int node = 0;
	static int ticks;

	ticks++;

	node = find_node();

	if (node < 0)
		LOG_ERR("Invalid node id, node with matching prop not found");
	else
		color = find_color(node, ticks);

	led_set_color(color);
}

/* Called by hook task every TICK */
static void led_tick(void)
{
	if (led_auto_control_is_enabled(EC_LED_ID_BATTERY_LED))
		board_led_set_color();
}
DECLARE_HOOK(HOOK_SECOND, led_tick, HOOK_PRIO_DEFAULT);

void led_control(enum ec_led_id led_id, enum ec_led_state state)
{
	enum led_color color;

	if ((led_id != EC_LED_ID_RECOVERY_HW_REINIT_LED) &&
	    (led_id != EC_LED_ID_SYSRQ_DEBUG_LED))
		return;

	if (state == LED_STATE_RESET) {
		led_auto_control(EC_LED_ID_BATTERY_LED, 1);
		board_led_set_color();
		return;
	}

	color = state ? LED_BLUE : LED_OFF;

	led_auto_control(EC_LED_ID_BATTERY_LED, 0);

	led_set_color(color);
}
```

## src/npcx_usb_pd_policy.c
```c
/* Copyright 2022 The ChromiumOS Authors
 * Use of this source code is governed by a BSD-style license that can be
 * found in the LICENSE file.
 */

#include "baseboard_usbc_config.h"
#include "driver/tcpm/rt1718s.h"
#include "driver/tcpm/tcpm.h"
#include "usb_pd.h"
#include "usbc_ppc.h"

#include "baseboard_usbc_config.h"

#define CPRINTS(format, args...) cprints(CC_USBCHARGE, format, ##args)
#define CPRINTF(format, args...) cprintf(CC_USBCHARGE, format, ##args)

void pd_power_supply_reset(int port)
{
	int prev_en;

	prev_en = ppc_is_sourcing_vbus(port);

	if (port == USBC_PORT_C1) {
		rt1718s_gpio_set_level(port, GPIO_EN_USB_C1_SOURCE, 0);
	}

	/* Disable VBUS. */
	ppc_vbus_source_enable(port, 0);

	/* Enable discharge if we were previously sourcing 5V */
	if (prev_en) {
		pd_set_vbus_discharge(port, 1);
	}

	/* Notify host of power info change. */
	pd_send_host_event(PD_EVENT_POWER_CHANGE);
}

int pd_set_power_supply_ready(int port)
{
	int rv;

	/* Disable charging. */
	rv = ppc_vbus_sink_enable(port, 0);
	if (rv) {
		return rv;
	}

	pd_set_vbus_discharge(port, 0);

	/* Provide Vbus. */
	if (port == USBC_PORT_C1) {
		rt1718s_gpio_set_level(port, GPIO_EN_USB_C1_SOURCE, 1);
	}

	rv = ppc_vbus_source_enable(port, 1);
	if (rv) {
		return rv;
	}

	/* Notify host of power info change. */
	pd_send_host_event(PD_EVENT_POWER_CHANGE);

	return EC_SUCCESS;
}

int pd_snk_is_vbus_provided(int port)
{
	/* TODO: use ADC? */
	return tcpm_check_vbus_level(port, VBUS_PRESENT);
}
```

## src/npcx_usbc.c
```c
/* Copyright 2022 The ChromiumOS Authors
 * Use of this source code is governed by a BSD-style license that can be
 * found in the LICENSE file.
 */

/* Kingler board-specific USB-C configuration */

/* TODO(b/220196310): Create GPIO driver for RT17181S TCPC */
#ifdef __REQUIRE_ZEPHYR_GPIOS__
#undef __REQUIRE_ZEPHYR_GPIOS__
#endif

#include "baseboard_usbc_config.h"
#include "console.h"
#include "driver/ppc/nx20p348x.h"
#include "driver/tcpm/anx7447.h"
#include "driver/tcpm/rt1718s.h"
#include "driver/usb_mux/ps8743_public.h"
#include "gpio.h"
#include "gpio/gpio_int.h"
#include "hooks.h"
#include "timer.h"
#include "usb_charge.h"
#include "usb_mux.h"
#include "usb_pd_tcpm.h"
#include "usbc_ppc.h"

#include "baseboard_usbc_config.h"
#include "variant_db_detection.h"

/* TODO(b/220196310): Create GPIO driver for RT17181S TCPC */
#ifdef __REQUIRE_ZEPHYR_GPIOS__
#undef __REQUIRE_ZEPHYR_GPIOS__
#endif
#include "gpio.h"

#define CPRINTS(format, args...) cprints(CC_USBPD, format, ##args)
#define CPRINTF(format, args...) cprintf(CC_USBPD, format, ##args)

/* USB Mux */

/* USB Mux C1 : board_init of PS8743 */
int ps8743_mux_1_board_init(const struct usb_mux *me)
{
	ps8743_tune_usb_eq(me, PS8743_USB_EQ_TX_3_6_DB,
			   PS8743_USB_EQ_RX_16_0_DB);

	return EC_SUCCESS;
}

void board_usb_mux_init(void)
{
	if (corsola_get_db_type() == CORSOLA_DB_TYPEC) {
		/* Disable DCI function. This is not needed for ARM. */
		ps8743_field_update(usb_muxes[1].mux, PS8743_REG_DCI_CONFIG_2,
				    PS8743_AUTO_DCI_MODE_MASK,
				    PS8743_AUTO_DCI_MODE_FORCE_USB);
	}
}
DECLARE_HOOK(HOOK_INIT, board_usb_mux_init, HOOK_PRIO_INIT_I2C + 1);

void board_tcpc_init(void)
{
	/* Only reset TCPC if not sysjump */
	if (!system_jumped_late()) {
		/* TODO(crosbug.com/p/61098): How long do we need to wait? */
		board_reset_pd_mcu();
	}

	/* Enable TCPC interrupts */
	gpio_enable_dt_interrupt(GPIO_INT_FROM_NODELABEL(int_usb_c0_tcpc));
	if (corsola_get_db_type() == CORSOLA_DB_TYPEC) {
		gpio_enable_dt_interrupt(
			GPIO_INT_FROM_NODELABEL(int_usb_c1_tcpc));
	}

	/* Enable BC1.2 interrupts. */
	gpio_enable_dt_interrupt(GPIO_INT_FROM_NODELABEL(int_usb_c0_bc12));

	/*
	 * Initialize HPD to low; after sysjump SOC needs to see
	 * HPD pulse to enable video path
	 */
	for (int port = 0; port < CONFIG_USB_PD_PORT_MAX_COUNT; ++port) {
		usb_mux_hpd_update(port, USB_PD_MUX_HPD_LVL_DEASSERTED |
						 USB_PD_MUX_HPD_IRQ_DEASSERTED);
	}
}
DECLARE_HOOK(HOOK_INIT, board_tcpc_init, HOOK_PRIO_POST_I2C);

__override int board_rt1718s_init(int port)
{
	static bool gpio_initialized;

	if (!system_jumped_late() && !gpio_initialized) {
		/* set GPIO 1~3 as push pull, as output, output low. */
		rt1718s_gpio_set_flags(port, RT1718S_GPIO1, GPIO_OUT_LOW);
		rt1718s_gpio_set_flags(port, RT1718S_GPIO2, GPIO_OUT_LOW);
		rt1718s_gpio_set_flags(port, RT1718S_GPIO3, GPIO_OUT_LOW);
		gpio_initialized = true;
	}

	/* gpio1 low, gpio2 output high when receiving frs signal */
	RETURN_ERROR(rt1718s_update_bits8(port, RT1718S_GPIO1_VBUS_CTRL,
					  RT1718S_GPIO1_VBUS_CTRL_FRS_RX_VBUS,
					  0));
	RETURN_ERROR(rt1718s_update_bits8(port, RT1718S_GPIO2_VBUS_CTRL,
					  RT1718S_GPIO2_VBUS_CTRL_FRS_RX_VBUS,
					  0xFF));

	/* Trigger GPIO 1/2 change when FRS signal received */
	RETURN_ERROR(rt1718s_update_bits8(
		port, RT1718S_FRS_CTRL3,
		RT1718S_FRS_CTRL3_FRS_RX_WAIT_GPIO2 |
			RT1718S_FRS_CTRL3_FRS_RX_WAIT_GPIO1,
		RT1718S_FRS_CTRL3_FRS_RX_WAIT_GPIO2 |
			RT1718S_FRS_CTRL3_FRS_RX_WAIT_GPIO1));
	/* Set FRS signal detect time to 46.875us */
	RETURN_ERROR(rt1718s_update_bits8(port, RT1718S_FRS_CTRL1,
					  RT1718S_FRS_CTRL1_FRSWAPRX_MASK,
					  0xFF));

	/* Disable BC1.2 SRC mode */
	RETURN_ERROR(rt1718s_update_bits8(port, RT1718S_RT2_BC12_SRC_FUNC,
					  RT1718S_RT2_BC12_SRC_FUNC_BC12_SRC_EN,
					  0));

	return EC_SUCCESS;
}

__override int board_rt1718s_set_frs_enable(int port, int enable)
{
	if (port == USBC_PORT_C1)
		/*
		 * Use set_flags (implemented by a single i2c write) instead
		 * of set_level (= i2c_update) to save one read operation in
		 * FRS path.
		 */
		rt1718s_gpio_set_flags(port, GPIO_EN_USB_C1_FRS,
				       enable ? GPIO_OUT_HIGH : GPIO_OUT_LOW);
	return EC_SUCCESS;
}

void board_reset_pd_mcu(void)
{
	CPRINTS("Resetting TCPCs...");
	/* reset C0 ANX3447 */
	/* Assert reset */
	gpio_pin_set_dt(GPIO_DT_FROM_NODELABEL(gpio_usb_c0_tcpc_rst), 1);
	msleep(1);
	gpio_pin_set_dt(GPIO_DT_FROM_NODELABEL(gpio_usb_c0_tcpc_rst), 0);
	/* After TEST_R release, anx7447/3447 needs 2ms to finish eFuse
	 * loading.
	 */
	msleep(2);

	/* reset C1 RT1718s */
	rt1718s_sw_reset(USBC_PORT_C1);
}

/* Used by Vbus discharge common code with CONFIG_USB_PD_DISCHARGE */
int board_vbus_source_enabled(int port)
{
	return ppc_is_sourcing_vbus(port);
}

__override int board_rt1718s_set_snk_enable(int port, int enable)
{
	if (port == USBC_PORT_C1) {
		rt1718s_gpio_set_level(port, GPIO_EN_USB_C1_SINK, enable);
	}

	return EC_SUCCESS;
}

int board_set_active_charge_port(int port)
{
	int i;
	bool is_valid_port =
		(port >= 0 && port < board_get_usb_pd_port_count());

	if (!is_valid_port && port != CHARGE_PORT_NONE) {
		return EC_ERROR_INVAL;
	}

	if (port == CHARGE_PORT_NONE) {
		CPRINTS("Disabling all charger ports");

		/* Disable all ports. */
		for (i = 0; i < board_get_usb_pd_port_count(); i++) {
			/*
			 * Do not return early if one fails otherwise we can
			 * get into a boot loop assertion failure.
			 */
			if (ppc_vbus_sink_enable(i, 0)) {
				CPRINTS("Disabling C%d as sink failed.", i);
			}
		}

		return EC_SUCCESS;
	}

	/* Check if the port is sourcing VBUS. */
	if (ppc_is_sourcing_vbus(port)) {
		CPRINTS("Skip enable C%d", port);
		return EC_ERROR_INVAL;
	}

	CPRINTS("New charge port: C%d", port);

	/*
	 * Turn off the other ports' sink path FETs, before enabling the
	 * requested charge port.
	 */
	for (i = 0; i < board_get_usb_pd_port_count(); i++) {
		if (i == port) {
			continue;
		}

		if (ppc_vbus_sink_enable(i, 0)) {
			CPRINTS("C%d: sink path disable failed.", i);
		}
	}

	/* Enable requested charge port. */
	if (ppc_vbus_sink_enable(port, 1)) {
		CPRINTS("C%d: sink path enable failed.", port);
		return EC_ERROR_UNKNOWN;
	}

	return EC_SUCCESS;
}

uint16_t tcpc_get_alert_status(void)
{
	uint16_t status = 0;

	if (!gpio_pin_get_dt(
		    GPIO_DT_FROM_NODELABEL(gpio_usb_c0_tcpc_int_odl))) {
		if (!gpio_pin_get_dt(
			    GPIO_DT_FROM_NODELABEL(gpio_usb_c0_tcpc_rst))) {
			status |= PD_STATUS_TCPC_ALERT_0;
		}
	}

	if (!gpio_pin_get_dt(
		    GPIO_DT_FROM_NODELABEL(gpio_usb_c1_tcpc_int_odl))) {
		return status |= PD_STATUS_TCPC_ALERT_1;
	}
	return status;
}

void ppc_interrupt(enum gpio_signal signal)
{
	switch (signal) {
	case GPIO_SIGNAL(DT_NODELABEL(gpio_usb_c0_ppc_int_odl)):
		ppc_chips[0].drv->interrupt(0);
		break;
	case GPIO_SIGNAL(DT_ALIAS(gpio_usb_c1_ppc_int_odl)):
		ppc_chips[1].drv->interrupt(1);
		break;
	default:
		break;
	}
}

void bc12_interrupt(enum gpio_signal signal)
{
	usb_charger_task_set_event(0, USB_CHG_EVENT_BC12);
}

__override int board_get_vbus_voltage(int port)
{
	int voltage = 0;
	int rv;

	switch (port) {
	case USBC_PORT_C0:
		rv = tcpc_config[USBC_PORT_C0].drv->get_vbus_voltage(port,
								     &voltage);
		if (rv)
			return 0;
		break;
	case USBC_PORT_C1:
		rt1718s_get_adc(port, RT1718S_ADC_VBUS1, &voltage);
		break;
	default:
		return 0;
	}
	return voltage;
}

__override int board_nx20p348x_init(int port)
{
	int rv;

	rv = i2c_update8(ppc_chips[port].i2c_port,
			 ppc_chips[port].i2c_addr_flags,
			 NX20P348X_DEVICE_CONTROL_REG, NX20P348X_CTRL_LDO_SD,
			 MASK_SET);
	return rv;
}
```

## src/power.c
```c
/* Copyright 2022 The ChromiumOS Authors. All rights reserved.
 * Use of this source code is governed by a BSD-style license that can be
 * found in the LICENSE file.
 */

#include <zephyr/init.h>
#include <zephyr/drivers/gpio.h>

#include <ap_power/ap_power.h>
#include "power.h"
#include "task.h"
#include "gpio.h"

static void board_power_change(struct ap_power_ev_callback *cb,
			       struct ap_power_ev_data data)
{
	switch (data.event) {
	default:
		return;

	case AP_POWER_PRE_INIT:
		/* Turn on the 3.3V rail */
		gpio_pin_set_dt(GPIO_DT_FROM_NODELABEL(gpio_en_pp3300_a), 1);

		/* Turn on the 5V rail. */
#ifdef CONFIG_POWER_PP5000_CONTROL
		power_5v_enable(task_get_current(), 1);
#else /* !defined(CONFIG_POWER_PP5000_CONTROL) */
		gpio_pin_set_dt(GPIO_DT_FROM_NODELABEL(gpio_en_pp5000_a), 1);
#endif /* defined(CONFIG_POWER_PP5000_CONTROL) */
		break;

	case AP_POWER_SHUTDOWN_COMPLETE:
		/* Turn off the 5V rail. */
#ifdef CONFIG_POWER_PP5000_CONTROL
		power_5v_enable(task_get_current(), 0);
#else /* !defined(CONFIG_POWER_PP5000_CONTROL) */
		gpio_pin_set_dt(GPIO_DT_FROM_NODELABEL(gpio_en_pp5000_a), 0);
#endif /* defined(CONFIG_POWER_PP5000_CONTROL) */

		/* Turn off the 3.3V and 5V rails. */
		gpio_pin_set_dt(GPIO_DT_FROM_NODELABEL(gpio_en_pp3300_a), 0);
		break;
	}
}

static int board_power_handler_init(const struct device *unused)
{
	static struct ap_power_ev_callback cb;

	/* Setup a suspend/resume callback */
	ap_power_ev_init_callback(&cb, board_power_change,
				  AP_POWER_PRE_INIT |
					  AP_POWER_SHUTDOWN_COMPLETE);
	ap_power_ev_add_callback(&cb);
	return 0;
}
SYS_INIT(board_power_handler_init, APPLICATION, 1);
```

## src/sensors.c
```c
/* Copyright 2021 The Chromium OS Authors. All rights reserved.
 * Use of this source code is governed by a BSD-style license that can be
 * found in the LICENSE file.
 */

#include "motion_sense.h"
#include "hooks.h"
#include "tablet_mode.h"
#include "sku.h"

static void board_update_sensor_config_from_sku(void)
{
	if (board_is_clamshell()) {
		motion_sensor_count = 0;
		gmr_tablet_switch_disable();
		/* The sensors are not stuffed; don't allow lines to float */
		gpio_set_flags(GPIO_ACCEL_GYRO_INT_L,
			       GPIO_INPUT | GPIO_PULL_DOWN);
		gpio_set_flags(GPIO_LID_ACCEL_INT_L,
			       GPIO_INPUT | GPIO_PULL_DOWN);
	} else {
		motion_sensors_detect_alt();
		/* Enable interrupt for the base accel sensor */
		gpio_enable_interrupt(GPIO_ACCEL_GYRO_INT_L);
	}
}
DECLARE_HOOK(HOOK_INIT, board_update_sensor_config_from_sku,
	     HOOK_PRIO_INIT_I2C + 2);
```

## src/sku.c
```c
/* Copyright 2022 The ChromiumOS Authors. All rights reserved.
 * Use of this source code is governed by a BSD-style license that can be
 * found in the LICENSE file.
 */

#include "common.h"
#include "config.h"
#include "console.h"
#include "driver/ln9310.h"
#include "tcpm/ps8xxx_public.h"
#include "hooks.h"
#include "sku.h"
#include "system.h"
#include "util.h"

#define CPRINTS(format, args...) cprints(CC_USBCHARGE, format, ##args)
#define CPRINTF(format, args...) cprintf(CC_USBCHARGE, format, ##args)

static uint8_t sku_id;

enum board_model {
	LAZOR,
	LIMOZEEN,
	UNKNOWN,
};

static const char *const model_name[] = {
	"LAZOR",
	"LIMOZEEN",
	"UNKNOWN",
};

static enum board_model get_model(void)
{
	if (sku_id == 0 || sku_id == 1 || sku_id == 2 || sku_id == 3)
		return LAZOR;
	if (sku_id == 4 || sku_id == 5 || sku_id == 6)
		return LIMOZEEN;
	return UNKNOWN;
}

/* Read SKU ID from GPIO and initialize variables for board variants */
static void sku_init(void)
{
	sku_id = system_get_sku_id();
	CPRINTS("SKU: %u (%s)", sku_id, model_name[get_model()]);
}
DECLARE_HOOK(HOOK_INIT, sku_init, HOOK_PRIO_POST_I2C);

enum battery_cell_type board_get_battery_cell_type(void)
{
	switch (get_model()) {
	case LIMOZEEN:
		return BATTERY_CELL_TYPE_3S;
	default:
		return BATTERY_CELL_TYPE_UNKNOWN;
	}
}

int board_is_clamshell(void)
{
	return get_model() == LIMOZEEN;
}

__override uint16_t board_get_ps8xxx_product_id(int port)
{
	/*
	 * Lazor (SKU_ID: 0, 1, 2, 3) rev 3+ changes TCPC from PS8751 to
	 * PS8805.
	 *
	 * Limozeen (SKU_ID: 4, 5, 6) all-rev uses PS8805.
	 */
	if (get_model() == LAZOR && system_get_board_version() < 3)
		return PS8751_PRODUCT_ID;

	return PS8805_PRODUCT_ID;
}

int board_has_da9313(void)
{
	return get_model() == LAZOR;
}

int board_has_buck_ic(void)
{
	return get_model() == LIMOZEEN && system_get_board_version() >= 8;
}

int board_has_ln9310(void)
{
	return get_model() == LIMOZEEN && system_get_board_version() < 8;
}
```
